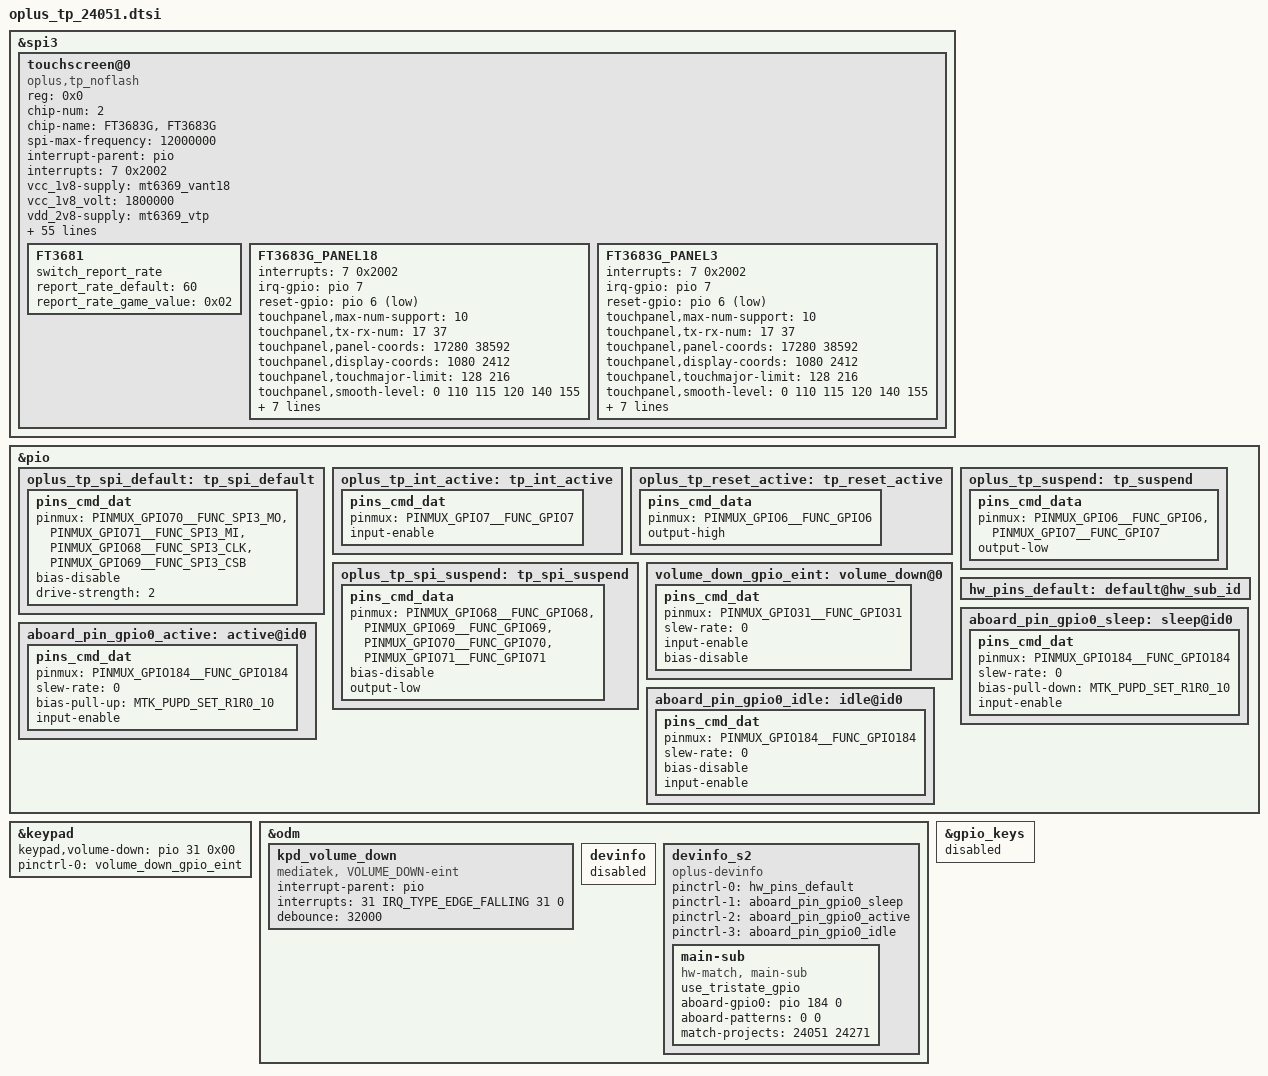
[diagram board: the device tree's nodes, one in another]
&spi3 {
	status = "okay";
	#address-cells = <1>;
	#size-cells = <0>;

	touchscreen@0{
		compatible = "oplus,tp_noflash";
		reg = <0x0>;
		chip-num = <2>;
		chip-name = "FT3683G", "FT3683G";
		status = "okay";
		spi-max-frequency = <12000000>;
		/* Interrupt && Irq-gpio */
		interrupt-parent = <&pio>;
		interrupts = <7 0x2002>;

		/* Power Config */
		vcc_1v8-supply  = <&mt6369_vant18>;
		vcc_1v8_volt = <1800000>;
		vdd_2v8-supply  = <&mt6369_vtp>;
		vdd_2v8_volt = <3300000>;


		/* Other HW Resource */

		irq-gpio = <&pio 7 0x2002>;
		reset-gpio = <&pio 6 0x1>;

		pinctrl-names = "default",  "sleep";
		pinctrl-0 = <&oplus_tp_int_active &oplus_tp_reset_active &oplus_tp_spi_default>;
		pinctrl-1 = <&oplus_tp_suspend &oplus_tp_spi_suspend>;

		touchpanel,max-num-support = <10>;
		touchpanel,tx-rx-num = <17 37>;
		touchpanel,panel-coords = <17280 38592>;
		touchpanel,display-coords = <1080 2412>;
		touchpanel,touchmajor-limit = <128 216>;
		//touchpanel,elimination-range = <20 200 200>;
		//touchpanel,int-mode = <1>; /*0: interrupt and disable, 1:interrupt and not disable*/
		touchpanel,smooth-level = <0 110 115 120 140 155>;
		touchpanel,smooth-level-charging = <0 110 115 120 140 155>;
		touchpanel,sensitive-level = <0 19 16 12 11 10>;
		touchpanel,tp-index = <0>;
		touchpanel,high-frame-rate-time = <60>;
		disable_suspend_irq_handler_support;

		vid_len = <2>;
		firmware_name = "AC234001", "AC234001";
		panel_type = <18 3>; /* panel-BOE*/
		platform_support_project = <24051 24271>;
		platform_support_project_dir = <24051 24051>;
		platform_support_project_commandline = "ac234_p_b_a0012_cmd_panel", "ac234_p_3_a0004_cmd_panel";


		/*
		 *Virtual Key Config:
		 *1:touchpanel,button-type: <virtualkey_type  supportted_button-map>
		 *virtualkey_type:
		 *Type 1: using board_properties
		 *Type 2: using same IC (button zone&& touch zone are seprate)
		 *Type 3: using diffrent IC (button zone&& touch zone are seprate)
		 *Type 4: No need of virtual key process
		 *supportted_button-map:select|menu|home|back
		 *
		 *2:touchpanel,button-map
		 *type (X1,Y1)(X2,Y2)(X3,Y3)(Width_X,Hight_Y)--Only when button-type is 0
		 */
		touchpanel,button-type = <4>;
		touchpanel.button-TRx = <0 0>;

		health_monitor_support;
		black_gesture_support;
		charger_pump_support;
		//lcd_tp_refresh_support;
		fw_update_app_support;
		smart_gesture_support;
		game_switch_support;
		report_flow_unlock_support;
		fingerprint_underscreen_support;
		pressure_report_support;
		touchpanel,single-optimized-time = <8>;
		//report_rate_white_list_support;
		auto_test_force_pass_support;
		snr_read_support;
		//high_resolution_support;
		screenoff_fingerprint_info_support;
		irq_need_dev_resume_ok;
		sportify_aod_gesture_support;
		black_gesture_indep_support;
		thermal_detect_support;
		exception_upload_support;
		tp_data_record_support;
		palm_to_sleep_support;
		glove_mode_v2_support;
		freq_hop_simulate_support;
		fw_edge_limit_support;
		temperature_detect_support;
		temperature_detect_shellback_support;
		disable_touch_event_support;



		FT3681 {
			switch_report_rate;
			report_rate_default = <60>;
			report_rate_game_value = <0x02>;
		};

		FT3683G_PANEL18 {
			interrupts = <7 0x2002>;
			irq-gpio = <&pio 7 0x2002>;
			reset-gpio = <&pio 6 0x1>;

			touchpanel,max-num-support = <10>;
			touchpanel,tx-rx-num = <17 37>;
			touchpanel,panel-coords = <17280 38592>;
			touchpanel,display-coords = <1080 2412>;
			touchpanel,touchmajor-limit = <128 216>;
			//touchpanel,elimination-range = <20 200 200>;
			//touchpanel,int-mode = <1>; /*0: interrupt and disable, 1:interrupt and not disable*/
			touchpanel,smooth-level = <0 110 115 120 140 155>;
			touchpanel,smooth-level-charging = <0 110 115 120 140 155>;
			touchpanel,sensitive-level = <0 19 16 12 11 10>;
			touchpanel,tp-index = <0>;
			touchpanel,high-frame-rate-time = <60>;
			touchpanel,single-optimized-time = <8>;

			tp_data_record_support;
		};


		FT3683G_PANEL3 {
			interrupts = <7 0x2002>;
			irq-gpio = <&pio 7 0x2002>;
			reset-gpio = <&pio 6 0x1>;

			touchpanel,max-num-support = <10>;
			touchpanel,tx-rx-num = <17 37>;
			touchpanel,panel-coords = <17280 38592>;
			touchpanel,display-coords = <1080 2412>;
			touchpanel,touchmajor-limit = <128 216>;
			//touchpanel,elimination-range = <20 200 200>;
			//touchpanel,int-mode = <1>; /*0: interrupt and disable, 1:interrupt and not disable*/
			touchpanel,smooth-level = <0 110 115 120 140 155>;
			touchpanel,smooth-level-charging = <0 110 115 120 140 155>;
			touchpanel,sensitive-level = <0 19 16 12 11 10>;
			touchpanel,tp-index = <0>;
			touchpanel,high-frame-rate-time = <60>;
			touchpanel,single-optimized-time = <8>;

			tp_data_record_support;
		};
	};
};

&pio {
	oplus_tp_spi_default: tp_spi_default {
		pins_cmd_dat {
			pinmux = <PINMUX_GPIO70__FUNC_SPI3_MO>,
				<PINMUX_GPIO71__FUNC_SPI3_MI>,
				<PINMUX_GPIO68__FUNC_SPI3_CLK>,
				<PINMUX_GPIO69__FUNC_SPI3_CSB>;
			bias-disable;
			drive-strength = <2>;
		};
	};

	oplus_tp_int_active: tp_int_active {
		pins_cmd_dat {
			pinmux = <PINMUX_GPIO7__FUNC_GPIO7>;
			input-enable;
		};
	};
	oplus_tp_reset_active: tp_reset_active {
		pins_cmd_data {
			pinmux = <PINMUX_GPIO6__FUNC_GPIO6>;
			output-high;
		};
	};
	oplus_tp_suspend: tp_suspend {
		pins_cmd_data {
			pinmux = <PINMUX_GPIO6__FUNC_GPIO6>,
					<PINMUX_GPIO7__FUNC_GPIO7>;
			output-low;
		};
	};
	oplus_tp_spi_suspend: tp_spi_suspend {
		pins_cmd_data {
			pinmux = <PINMUX_GPIO68__FUNC_GPIO68>,
					<PINMUX_GPIO69__FUNC_GPIO69>,
					<PINMUX_GPIO70__FUNC_GPIO70>,
					<PINMUX_GPIO71__FUNC_GPIO71>;
			bias-disable;
			output-low;
		};
	};
};

&keypad {
        keypad,volume-down = <&pio 31 0x00>;
        pinctrl-names = "volume_down_as_int";
        pinctrl-0 = <&volume_down_gpio_eint>;
        status = "okay";
};

&pio {
        volume_down_gpio_eint:volume_down@0{
                pins_cmd_dat {
                        pinmux = <PINMUX_GPIO31__FUNC_GPIO31>;
                        slew-rate = <0>;  /*direction 0:in, 1:out*/
                        input-enable;
                        bias-disable;
                };
        };
};

&odm {
        kpd_volume_down:kpd_volume_down {
                compatible = "mediatek, VOLUME_DOWN-eint";
                interrupt-parent = <&pio>;
                interrupts = <31 IRQ_TYPE_EDGE_FALLING 31 0>;
                debounce = <32000>;
                status = "okay";
        };
};

&odm {
	devinfo {
		status = "disabled";
	};

	devinfo_s2 {
		compatible = "oplus-devinfo";

		pinctrl-names = "default", "aboard_gpio0_sleep", "aboard_gpio0_active", "aboard_gpio0_idle";
		pinctrl-0 = <&hw_pins_default>;
		pinctrl-1 = <&aboard_pin_gpio0_sleep>;
		pinctrl-2 = <&aboard_pin_gpio0_active>;
		pinctrl-3 = <&aboard_pin_gpio0_idle>;

		main-sub {
			compatible = "hw-match, main-sub";
			use_tristate_gpio;
			aboard-gpio0 = <&pio 184 0>;
			aboard-patterns = <0 0>;	/*0[high-resistance] 1[pull-down] 2[pull-up]*/
			/*main board*/
			match-projects = <24051 24271>;
		};
	};
};

&pio{
	hw_pins_default:default@hw_sub_id {
	};

	aboard_pin_gpio0_sleep:sleep@id0 {
		pins_cmd_dat {
			pinmux = <PINMUX_GPIO184__FUNC_GPIO184>;
			slew-rate = <0>;
			bias-pull-down = <MTK_PUPD_SET_R1R0_10>;
			input-enable;
		};
	};

	aboard_pin_gpio0_active:active@id0 {
		pins_cmd_dat {
			pinmux = <PINMUX_GPIO184__FUNC_GPIO184>;
			slew-rate = <0>;
			bias-pull-up = <MTK_PUPD_SET_R1R0_10>;
			input-enable;
		};
	};

	aboard_pin_gpio0_idle:idle@id0 {
		pins_cmd_dat {
			pinmux = <PINMUX_GPIO184__FUNC_GPIO184>;
			slew-rate = <0>;
			bias-disable;
			input-enable;
		};
	};
};

&gpio_keys {
	status = "disabled";
};
